# RZT2ME register map
Vendor: Renesas Electronics Corporation; Series: RZT; File version: 1.00.00
CPU: other r0p0, little endian, MPU, no FPU, VTOR, 4 interrupt priority bits, 624 interrupts
Registers are 32-bit, read-write, reset 0x0 unless marked. A register's access mark holds for its fields unless they carry their own. Offsets are from the block's base; [hi:lo] are bit positions.

## MTU0 — Multi-Function Timer Pulse Unit Channel 0
Base 0x90001300
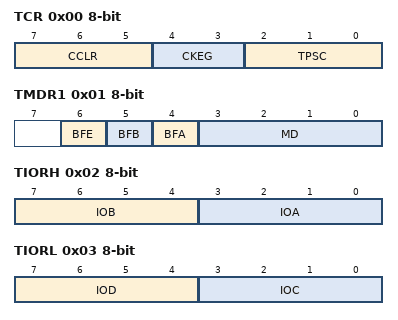
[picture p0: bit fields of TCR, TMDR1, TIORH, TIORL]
0x00 TCR 8-bit — Timer Control Register
  [7:5] CCLR — Counter Clear Source Select
  [4:3] CKEG — Clock Edge Select
    0=Count at rising edge; 1=Count at falling edge; 0b1x=Count at both edges
  [2:0] TPSC — Time Prescaler Select
0x01 TMDR1 8-bit — Timer Mode Register 1
  [6] BFE — Buffer Operation E
    0=MTU0.TGRE and MTU0.TGRF operate normally; 1=MTU0.TGRE and MTU0.TGRF used together for buffer operation
  [5] BFB — Buffer Operation B
    0=TGRB and TGRD operate normally; 1=TGRB and TGRD used together for buffer operation
  [4] BFA — Buffer Operation A
    0=TGRA and TGRC operate normally; 1=TGRA and TGRC used together for buffer operation
  [3:0] MD — Mode Select
0x02 TIORH 8-bit — Timer I/O Control Register H
  [7:4] IOB — I/O Control B
  [3:0] IOA — I/O Control A
0x03 TIORL 8-bit — Timer I/O Control Register L
  [7:4] IOD — I/O Control B
  [3:0] IOC — I/O Control A
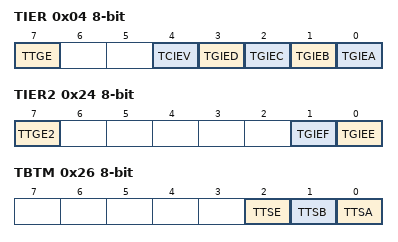
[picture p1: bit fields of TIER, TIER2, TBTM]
0x04 TIER 8-bit — Timer Interrupt Enable Register
  [7] TTGE — A/D Converter Start Request Enable
    0=A/D converter start request generation disabled; 1=A/D converter start request generation enabled
  [4] TCIEV — Overflow Interrupt Enable
    0=Interrupt requests (TCIV) disabled; 1=Interrupt requests (TCIV) enabled
  [3] TGIED — TGR Interrupt Enable D
    0=Interrupt requests (TGID) disabled; 1=Interrupt requests (TGID) enabled
  [2] TGIEC — TGR Interrupt Enable C
    0=Interrupt requests (TGIC) disabled; 1=Interrupt requests (TGIC) enabled
  [1] TGIEB — TGR Interrupt Enable B
    0=Interrupt requests (TGIB) disabled; 1=Interrupt requests (TGIB) enabled
  [0] TGIEA — TGR Interrupt Enable A
    0=Interrupt requests (TGIA) disabled; 1=Interrupt requests (TGIA) enabled
0x06 TCNT 16-bit — Timer Counter
0x08 TGRA 16-bit reset 0xFFFF — Timer General Register A
0x0A TGRB 16-bit reset 0xFFFF — Timer General Register B
0x0C TGRC 16-bit reset 0xFFFF — Timer General Register C
0x0E TGRD 16-bit reset 0xFFFF — Timer General Register D
0x20 TGRE 16-bit reset 0xFFFF — Timer General Register E
0x22 TGRF 16-bit reset 0xFFFF — Timer General Register F
0x24 TIER2 8-bit — Timer Interrupt Enable Register 2
  [7] TTGE2 — A/D Converter Start Request Enable 2
    0=A/D converter start request generation by compare match between MTU0.TCNT and MTU0.TGRE disabled; 1=A/D converter start request generation by compare match between MTU0.TCNT and MTU0.TGRE enabled
  [1] TGIEF — TGR Interrupt Enable F
    0=Interrupt requests (TGIF) disabled; 1=Interrupt requests (TGIF) enabled
  [0] TGIEE — TGR Interrupt Enable E
    0=Interrupt requests (TGIE) disabled; 1=Interrupt requests (TGIE) enabled
0x26 TBTM 8-bit — Timer Buffer Operation Transfer Mode Register
  [2] TTSE — Timing Select E
    0=When compare match E occurs in MTU0, data is transferred from MTU0.TGRF to MTU0.TGRE; 1=When MTU0.TCNT is cleared in MTU0, data is transferred from MTU0.TGRF to MTU0.TGRE
  [1] TTSB — Timing Select B
    0=When compare match B occurs in each channel, data is transferred from TGRD to TGRB; 1=When TCNT is cleared in each channel, data is transferred from TGRD to TGRB
  [0] TTSA — Timing Select A
    0=When compare match A occurs in each channel, data is transferred from TGRC to TGRA; 1=When TCNT is cleared in each channel, data is transferred from TGRC to TGRA
0x28 TCR2 8-bit — Timer Control Register 2
  [2:0] TPSC2 — Time Prescaler Select

## MTU8 — Multi-Function Timer Pulse Unit Channel 8
Base 0x90001600
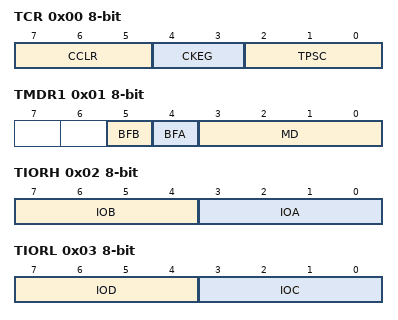
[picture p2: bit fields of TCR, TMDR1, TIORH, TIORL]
0x00 TCR 8-bit — Timer Control Register
  [7:5] CCLR — Counter Clear Source Select
  [4:3] CKEG — Clock Edge Select
    0=Count at rising edge; 1=Count at falling edge; 0b1x=Count at both edges
  [2:0] TPSC — Time Prescaler Select
0x01 TMDR1 8-bit — Timer Mode Register 1
  [5] BFB — Buffer Operation B
    0=TGRB and TGRD operate normally; 1=TGRB and TGRD used together for buffer operation
  [4] BFA — Buffer Operation A
    0=TGRA and TGRC operate normally; 1=TGRA and TGRC used together for buffer operation
  [3:0] MD — Mode Select
0x02 TIORH 8-bit — Timer I/O Control Register H
  [7:4] IOB — I/O Control B
  [3:0] IOA — I/O Control A
0x03 TIORL 8-bit — Timer I/O Control Register L
  [7:4] IOD — I/O Control B
  [3:0] IOC — I/O Control A
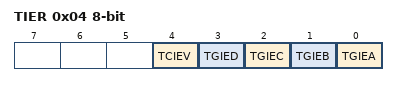
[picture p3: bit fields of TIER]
0x04 TIER 8-bit — Timer Interrupt Enable Register
  [4] TCIEV — Overflow Interrupt Enable
    0=Interrupt requests (TCIV) disabled; 1=Interrupt requests (TCIV) enabled
  [3] TGIED — TGR Interrupt Enable D
    0=Interrupt requests (TGID) disabled; 1=Interrupt requests (TGID) enabled
  [2] TGIEC — TGR Interrupt Enable C
    0=Interrupt requests (TGIC) disabled; 1=Interrupt requests (TGIC) enabled
  [1] TGIEB — TGR Interrupt Enable B
    0=Interrupt requests (TGIB) disabled; 1=Interrupt requests (TGIB) enabled
  [0] TGIEA — TGR Interrupt Enable A
    0=Interrupt requests (TGIA) disabled; 1=Interrupt requests (TGIA) enabled
0x06 TCR2 8-bit — Timer Control Register 2
  [2:0] TPSC2 — Time Prescaler Select
0x08 TCNT — Timer Counter
0x0C TGRA reset 0xFFFFFFFF — Timer General Register A
0x10 TGRB reset 0xFFFFFFFF — Timer General Register B
0x14 TGRC reset 0xFFFFFFFF — Timer General Register C
0x18 TGRD reset 0xFFFFFFFF — Timer General Register D
